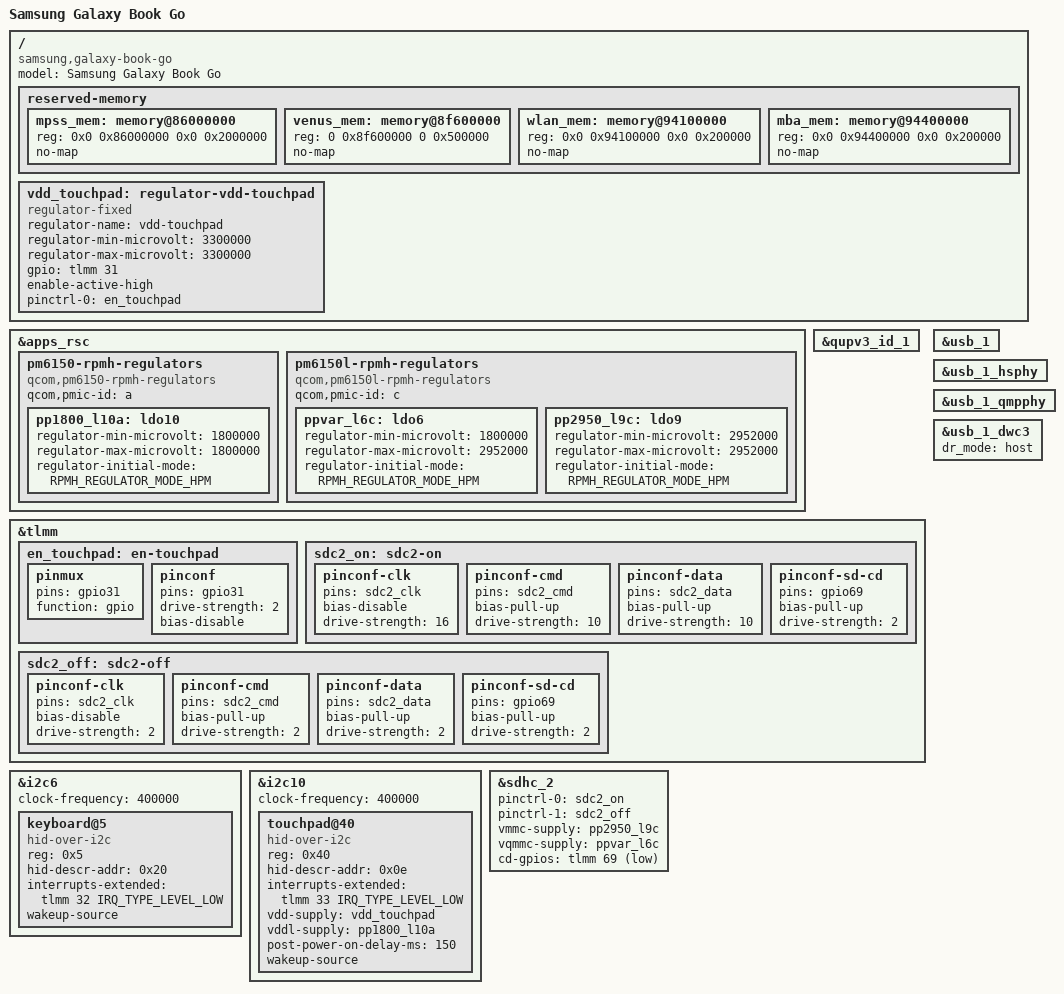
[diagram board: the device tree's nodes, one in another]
// SPDX-License-Identifier: BSD-3-Clause
/*
 * Samsung Galaxy Book Go (sc7180)  device tree source
 *
 * Copyright (c) 2019, The Linux Foundation. All rights reserved.
 */

/dts-v1/;
#include <dt-bindings/regulator/qcom,rpmh-regulator.h>
#include <dt-bindings/gpio/gpio.h>
#include "sc7180.dtsi"

/ {
	model = "Samsung Galaxy Book Go";
	compatible = "samsung,galaxy-book-go", "qcom,sc7180";

	reserved-memory {
		mpss_mem: memory@86000000 {
			/*
			  OVERLAP if this goes past 0x8b700000
			  So, size up to max of 0x83100000
			*/
			reg = <0x0 0x86000000 0x0 0x2000000>;
			no-map;
		};

		venus_mem: memory@8f600000 {
			reg = <0 0x8f600000 0 0x500000>;
			no-map;
		};

		wlan_mem: memory@94100000 {
			reg = <0x0 0x94100000 0x0 0x200000>;
			no-map;
		};

		mba_mem: memory@94400000 {
			reg = <0x0 0x94400000 0x0 0x200000>;
			no-map;
		};
	};

	vdd_touchpad: regulator-vdd-touchpad {
		compatible = "regulator-fixed";
		regulator-name = "vdd-touchpad";
		regulator-min-microvolt = <3300000>;
		regulator-max-microvolt = <3300000>;
		gpio = <&tlmm 31 GPIO_ACTIVE_HIGH>;
		/* add "enable-active-high;" when GPIO is active high */
		enable-active-high;
		pinctrl-names = "default";
		pinctrl-0 = <&en_touchpad>;
	};
};

&apps_rsc {
	pm6150-rpmh-regulators {
		compatible = "qcom,pm6150-rpmh-regulators";
		qcom,pmic-id = "a";

		pp1800_l10a: ldo10 {
			regulator-min-microvolt = <1800000>;
			regulator-max-microvolt = <1800000>;
			regulator-initial-mode = <RPMH_REGULATOR_MODE_HPM>;
		};
	};

	pm6150l-rpmh-regulators {
		compatible = "qcom,pm6150l-rpmh-regulators";
		qcom,pmic-id = "c";

		ppvar_l6c: ldo6 {
			regulator-min-microvolt = <1800000>;
			regulator-max-microvolt = <2952000>;
			regulator-initial-mode = <RPMH_REGULATOR_MODE_HPM>;
		};

		pp2950_l9c: ldo9 {
			regulator-min-microvolt = <2952000>;
			regulator-max-microvolt = <2952000>;
			regulator-initial-mode = <RPMH_REGULATOR_MODE_HPM>;
		};
	};
};

&qupv3_id_1 {
	status = "okay";
};

&tlmm {
	en_touchpad: en-touchpad {
		pinmux {
			pins = "gpio31";
			function = "gpio";
		};

		pinconf {
			pins = "gpio31";
			drive-strength = <2>;
			bias-disable;
		};
	};

	sdc2_on: sdc2-on {
		pinconf-clk {
			pins = "sdc2_clk";
			bias-disable;
			drive-strength = <16>;
		};

		pinconf-cmd {
			pins = "sdc2_cmd";
			bias-pull-up;
			drive-strength = <10>;
		};

		pinconf-data {
			pins = "sdc2_data";
			bias-pull-up;
			drive-strength = <10>;
		};

		pinconf-sd-cd {
			pins = "gpio69";
			bias-pull-up;
			drive-strength = <2>;
		};
	};

	sdc2_off: sdc2-off {
		pinconf-clk {
			pins = "sdc2_clk";
			bias-disable;
			drive-strength = <2>;
		};

		pinconf-cmd {
			pins = "sdc2_cmd";
			bias-pull-up;
			drive-strength = <2>;
		};

		pinconf-data {
			pins = "sdc2_data";
			bias-pull-up;
			drive-strength = <2>;
		};

		pinconf-sd-cd {
			pins = "gpio69";
			bias-pull-up;
			drive-strength = <2>;
		};
	};
};

&i2c6 {
	clock-frequency = <400000>;
	status = "okay";

	keyboard@5 {
		compatible = "hid-over-i2c";
		reg = <0x5>;
		hid-descr-addr = <0x20>;

		interrupts-extended = <&tlmm 32 IRQ_TYPE_LEVEL_LOW>;

		wakeup-source;
	};
};

&i2c10 {
	clock-frequency = <400000>;
	status = "okay";

	touchpad@40 {
		compatible = "hid-over-i2c";
		reg = <0x40>;
		hid-descr-addr = <0x0e>;

		interrupts-extended = <&tlmm 33 IRQ_TYPE_LEVEL_LOW>;

		vdd-supply = <&vdd_touchpad>;
		vddl-supply = <&pp1800_l10a>;
		post-power-on-delay-ms = <150>;

		wakeup-source;
	};
};

&usb_1 {
	status = "okay";
};

&usb_1_hsphy {
	status = "okay";
};

&usb_1_qmpphy {
	status = "okay";
};

&usb_1_dwc3 {
	dr_mode = "host";
};

&sdhc_2 {
	status = "okay";

	pinctrl-names = "default", "sleep";
	pinctrl-0 = <&sdc2_on>;
	pinctrl-1 = <&sdc2_off>;
	vmmc-supply = <&pp2950_l9c>;
	vqmmc-supply = <&ppvar_l6c>;

	cd-gpios = <&tlmm 69 GPIO_ACTIVE_LOW>;
};
